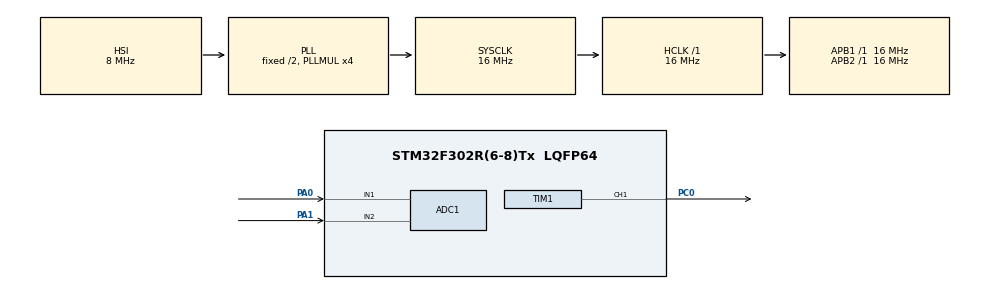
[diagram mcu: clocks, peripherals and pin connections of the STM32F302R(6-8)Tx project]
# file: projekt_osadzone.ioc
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ADC1.Channel-0\#ChannelRegularConversion=ADC_CHANNEL_1
ADC1.Channel-1\#ChannelRegularConversion=ADC_CHANNEL_2
ADC1.ClockPrescaler=ADC_CLOCK_ASYNC_DIV1
ADC1.ContinuousConvMode=ENABLE
ADC1.DMAContinuousRequests=ENABLE
ADC1.EnableInjectedConversion=DISABLE
ADC1.NbrOfConversion=2
ADC1.NbrOfConversionFlag=1
ADC1.Offset-0\#ChannelRegularConversion=0
ADC1.Offset-1\#ChannelRegularConversion=0
ADC1.OffsetNumber-0\#ChannelRegularConversion=ADC_OFFSET_NONE
ADC1.OffsetNumber-1\#ChannelRegularConversion=ADC_OFFSET_NONE
ADC1.Rank-0\#ChannelRegularConversion=1
ADC1.Rank-1\#ChannelRegularConversion=2
ADC1.SamplingTime-0\#ChannelRegularConversion=ADC_SAMPLETIME_1CYCLE_5
ADC1.SamplingTime-1\#ChannelRegularConversion=ADC_SAMPLETIME_1CYCLE_5
ADC1.SamplingTimeOPAMP-1\#ChannelRegularConversion=ADC_SAMPLETIME_7CYCLES_5
ADC1.SequencerNbRanks=2
ADC1.SubFamily=STM32F302x8
ADC1.master=1
Dma.ADC1.0.Direction=DMA_PERIPH_TO_MEMORY
Dma.ADC1.0.Instance=DMA1_Channel1
Dma.ADC1.0.MemDataAlignment=DMA_MDATAALIGN_HALFWORD
Dma.ADC1.0.MemInc=DMA_MINC_ENABLE
Dma.ADC1.0.Mode=DMA_CIRCULAR
Dma.ADC1.0.PeriphDataAlignment=DMA_PDATAALIGN_HALFWORD
Dma.ADC1.0.PeriphInc=DMA_PINC_DISABLE
Dma.ADC1.0.Priority=DMA_PRIORITY_LOW
Dma.Request0=ADC1
Mcu.Family=STM32F3
Mcu.Name=STM32F302R(6-8)Tx
Mcu.Package=LQFP64
NVIC.DMA1_Channel1_IRQn=true\:0\:0\:false\:false\:true\:false\:true\:true
NVIC.PriorityGroup=NVIC_PRIORITYGROUP_4
PA0.Mode=IN1-Single-Ended
PA0.Signal=ADC1_IN1
PA1.Mode=IN2-Single-Ended
PA1.Signal=ADC1_IN2
PA13.Mode=Serial_Wire
PA13.Signal=SYS_JTMS-SWDIO
PA14.Mode=Serial_Wire
PA14.Signal=SYS_JTCK-SWCLK
PC0.Signal=S_TIM1_CH1
ProjectManager.HeapSize=0x200
ProjectManager.StackSize=0x400
ProjectManager.TargetToolchain=STM32CubeIDE
RCC.AHBFreq_Value=16000000
RCC.APB1Freq_Value=16000000
RCC.APB1TimFreq_Value=16000000
RCC.APB2Freq_Value=16000000
RCC.APB2TimFreq_Value=16000000
RCC.CortexFreq_Value=16000000
RCC.HCLKFreq_Value=16000000
RCC.HSE_VALUE=8000000
RCC.HSI_VALUE=8000000
RCC.LSE_VALUE=32768
RCC.PLLMUL=RCC_PLL_MUL4
RCC.SYSCLKFreq_VALUE=16000000
RCC.SYSCLKSourceVirtual=RCC_SYSCLKSOURCE_PLLCLK
RCC.USBFreq_Value=16000000
SH.S_TIM1_CH1.0=TIM1_CH1,PWM Generation1 CH1
TIM1.Channel-PWM\ Generation1\ CH1=TIM_CHANNEL_1
TIM1.Period=6399
TIM1.Prescaler=49
VP_TIM1_VS_ClockSourceINT.Mode=Internal
board=custom

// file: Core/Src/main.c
/* USER CODE BEGIN Header */
/**
  ******************************************************************************
  * @file           : main.c
  * @brief          : Main program body
  ******************************************************************************
  * @attention
  *
  * Copyright (c) 2025 STMicroelectronics.
  * All rights reserved.
  *
  * This software is licensed under terms that can be found in the LICENSE file
  * in the root directory of this software component.
  * If no LICENSE file comes with this software, it is provided AS-IS.
  *
  ******************************************************************************
  */
/* USER CODE END Header */
#include "main.h"

ADC_HandleTypeDef hadc1;
DMA_HandleTypeDef hdma_adc1;

TIM_HandleTypeDef htim1;

/* USER CODE BEGIN PV */
volatile int16_t rawValueBuff[2];
/* USER CODE END PV */

void SystemClock_Config(void);
static void MX_GPIO_Init(void);
static void MX_DMA_Init(void);
static void MX_ADC1_Init(void);
static void MX_TIM1_Init(void);

/* USER CODE BEGIN 0 */
// Mapowanie wartości z ADC
int16_t map(int16_t pos){
	return 320 + ((int32_t)(pos + 4095) * (640 - 320)) / (2 * 4095);
}

/* USER CODE END 0 */

int main(void)
{

  /* MCU Configuration--------------------------------------------------------*/

  /* Reset of all peripherals, Initializes the Flash interface and the Systick. */
  HAL_Init();

  /* Configure the system clock */
  SystemClock_Config();

  /* Initialize all configured peripherals */
  MX_GPIO_Init();
  MX_DMA_Init();
  MX_ADC1_Init();
  MX_TIM1_Init();
  /* USER CODE BEGIN 2 */
  HAL_TIM_PWM_Start(&htim1, TIM_CHANNEL_1);
  HAL_ADC_Start_DMA(&hadc1,(uint32_t *) rawValueBuff, 2);
  /* USER CODE END 2 */

  /* Infinite loop */
  while (1)
  {

  }
}

void SystemClock_Config(void)
{
  RCC_OscInitTypeDef RCC_OscInitStruct = {0};
  RCC_ClkInitTypeDef RCC_ClkInitStruct = {0};
  RCC_PeriphCLKInitTypeDef PeriphClkInit = {0};

  /** Initializes the RCC Oscillators according to the specified parameters
  * in the RCC_OscInitTypeDef structure.
  */
  RCC_OscInitStruct.OscillatorType = RCC_OSCILLATORTYPE_HSI;
  RCC_OscInitStruct.HSIState = RCC_HSI_ON;
  RCC_OscInitStruct.HSICalibrationValue = RCC_HSICALIBRATION_DEFAULT;
  RCC_OscInitStruct.PLL.PLLState = RCC_PLL_ON;
  RCC_OscInitStruct.PLL.PLLSource = RCC_PLLSOURCE_HSI;
  RCC_OscInitStruct.PLL.PLLMUL = RCC_PLL_MUL4;
  if (HAL_RCC_OscConfig(&RCC_OscInitStruct) != HAL_OK)
  {
    Error_Handler();
  }

  /** Initializes the CPU, AHB and APB buses clocks
  */
  RCC_ClkInitStruct.ClockType = RCC_CLOCKTYPE_HCLK|RCC_CLOCKTYPE_SYSCLK
                              |RCC_CLOCKTYPE_PCLK1|RCC_CLOCKTYPE_PCLK2;
  RCC_ClkInitStruct.SYSCLKSource = RCC_SYSCLKSOURCE_PLLCLK;
  RCC_ClkInitStruct.AHBCLKDivider = RCC_SYSCLK_DIV1;
  RCC_ClkInitStruct.APB1CLKDivider = RCC_HCLK_DIV1;
  RCC_ClkInitStruct.APB2CLKDivider = RCC_HCLK_DIV1;

  if (HAL_RCC_ClockConfig(&RCC_ClkInitStruct, FLASH_LATENCY_0) != HAL_OK)
  {
    Error_Handler();
  }
  PeriphClkInit.PeriphClockSelection = RCC_PERIPHCLK_TIM1|RCC_PERIPHCLK_ADC1;
  PeriphClkInit.Tim1ClockSelection = RCC_TIM1CLK_HCLK;
  PeriphClkInit.Adc1ClockSelection = RCC_ADC1PLLCLK_DIV1;

  if (HAL_RCCEx_PeriphCLKConfig(&PeriphClkInit) != HAL_OK)
  {
    Error_Handler();
  }
}

static void MX_ADC1_Init(void)
{

  ADC_ChannelConfTypeDef sConfig = {0};

  /** Common config
  */
  hadc1.Instance = ADC1;
  hadc1.Init.ClockPrescaler = ADC_CLOCK_ASYNC_DIV1;
  hadc1.Init.Resolution = ADC_RESOLUTION_12B;
  hadc1.Init.ScanConvMode = ADC_SCAN_ENABLE;
  hadc1.Init.ContinuousConvMode = ENABLE;
  hadc1.Init.DiscontinuousConvMode = DISABLE;
  hadc1.Init.ExternalTrigConvEdge = ADC_EXTERNALTRIGCONVEDGE_NONE;
  hadc1.Init.ExternalTrigConv = ADC_SOFTWARE_START;
  hadc1.Init.DataAlign = ADC_DATAALIGN_RIGHT;
  hadc1.Init.NbrOfConversion = 2;
  hadc1.Init.DMAContinuousRequests = ENABLE;
  hadc1.Init.EOCSelection = ADC_EOC_SINGLE_CONV;
  hadc1.Init.LowPowerAutoWait = DISABLE;
  hadc1.Init.Overrun = ADC_OVR_DATA_OVERWRITTEN;
  if (HAL_ADC_Init(&hadc1) != HAL_OK)
  {
    Error_Handler();
  }

  /** Configure Regular Channel
  */
  sConfig.Channel = ADC_CHANNEL_1;
  sConfig.Rank = ADC_REGULAR_RANK_1;
  sConfig.SingleDiff = ADC_SINGLE_ENDED;
  sConfig.SamplingTime = ADC_SAMPLETIME_1CYCLE_5;
  sConfig.OffsetNumber = ADC_OFFSET_NONE;
  sConfig.Offset = 0;
  if (HAL_ADC_ConfigChannel(&hadc1, &sConfig) != HAL_OK)
  {
    Error_Handler();
  }

  /** Configure Regular Channel
  */
  sConfig.Channel = ADC_CHANNEL_2;
  sConfig.Rank = ADC_REGULAR_RANK_2;
  if (HAL_ADC_ConfigChannel(&hadc1, &sConfig) != HAL_OK)
  {
    Error_Handler();
  }

}

static void MX_TIM1_Init(void)
{

  TIM_ClockConfigTypeDef sClockSourceConfig = {0};
  TIM_MasterConfigTypeDef sMasterConfig = {0};
  TIM_OC_InitTypeDef sConfigOC = {0};
  TIM_BreakDeadTimeConfigTypeDef sBreakDeadTimeConfig = {0};

  htim1.Instance = TIM1;
  htim1.Init.Prescaler = 49;
  htim1.Init.CounterMode = TIM_COUNTERMODE_UP;
  htim1.Init.Period = 6399;
  htim1.Init.ClockDivision = TIM_CLOCKDIVISION_DIV1;
  htim1.Init.RepetitionCounter = 0;
  htim1.Init.AutoReloadPreload = TIM_AUTORELOAD_PRELOAD_DISABLE;
  if (HAL_TIM_Base_Init(&htim1) != HAL_OK)
  {
    Error_Handler();
  }
  sClockSourceConfig.ClockSource = TIM_CLOCKSOURCE_INTERNAL;
  if (HAL_TIM_ConfigClockSource(&htim1, &sClockSourceConfig) != HAL_OK)
  {
    Error_Handler();
  }
  if (HAL_TIM_PWM_Init(&htim1) != HAL_OK)
  {
    Error_Handler();
  }
  sMasterConfig.MasterOutputTrigger = TIM_TRGO_RESET;
  sMasterConfig.MasterOutputTrigger2 = TIM_TRGO2_RESET;
  sMasterConfig.MasterSlaveMode = TIM_MASTERSLAVEMODE_DISABLE;
  if (HAL_TIMEx_MasterConfigSynchronization(&htim1, &sMasterConfig) != HAL_OK)
  {
    Error_Handler();
  }
  sConfigOC.OCMode = TIM_OCMODE_PWM1;
  sConfigOC.Pulse = 0;
  sConfigOC.OCPolarity = TIM_OCPOLARITY_HIGH;
  sConfigOC.OCNPolarity = TIM_OCNPOLARITY_HIGH;
  sConfigOC.OCFastMode = TIM_OCFAST_DISABLE;
  sConfigOC.OCIdleState = TIM_OCIDLESTATE_RESET;
  sConfigOC.OCNIdleState = TIM_OCNIDLESTATE_RESET;
  if (HAL_TIM_PWM_ConfigChannel(&htim1, &sConfigOC, TIM_CHANNEL_1) != HAL_OK)
  {
    Error_Handler();
  }
  sBreakDeadTimeConfig.OffStateRunMode = TIM_OSSR_DISABLE;
  sBreakDeadTimeConfig.OffStateIDLEMode = TIM_OSSI_DISABLE;
  sBreakDeadTimeConfig.LockLevel = TIM_LOCKLEVEL_OFF;
  sBreakDeadTimeConfig.DeadTime = 0;
  sBreakDeadTimeConfig.BreakState = TIM_BREAK_DISABLE;
  sBreakDeadTimeConfig.BreakPolarity = TIM_BREAKPOLARITY_HIGH;
  sBreakDeadTimeConfig.BreakFilter = 0;
  sBreakDeadTimeConfig.Break2State = TIM_BREAK2_DISABLE;
  sBreakDeadTimeConfig.Break2Polarity = TIM_BREAK2POLARITY_HIGH;
  sBreakDeadTimeConfig.Break2Filter = 0;
  sBreakDeadTimeConfig.AutomaticOutput = TIM_AUTOMATICOUTPUT_DISABLE;
  if (HAL_TIMEx_ConfigBreakDeadTime(&htim1, &sBreakDeadTimeConfig) != HAL_OK)
  {
    Error_Handler();
  }
  HAL_TIM_MspPostInit(&htim1);

}

static void MX_DMA_Init(void)
{

  /* DMA controller clock enable */
  __HAL_RCC_DMA1_CLK_ENABLE();

  /* DMA interrupt init */
  /* DMA1_Channel1_IRQn interrupt configuration */
  HAL_NVIC_SetPriority(DMA1_Channel1_IRQn, 0, 0);
  HAL_NVIC_EnableIRQ(DMA1_Channel1_IRQn);

}

static void MX_GPIO_Init(void)
{

  /* GPIO Ports Clock Enable */
  __HAL_RCC_GPIOC_CLK_ENABLE();
  __HAL_RCC_GPIOA_CLK_ENABLE();

}

void Error_Handler(void)
{
  __disable_irq();
  while (1)
  {
  }
}
